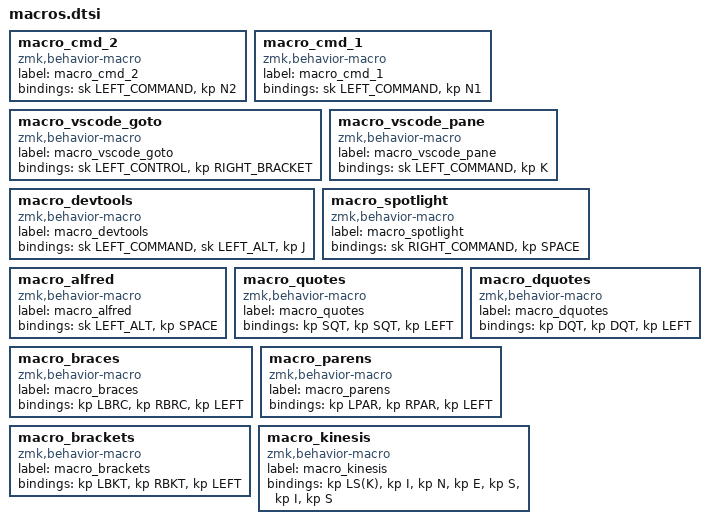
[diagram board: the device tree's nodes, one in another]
macro_cmd_2: macro_cmd_2{
compatible = "zmk,behavior-macro";
label = "macro_cmd_2";
#binding-cells = <0>;
bindings = <&sk LEFT_COMMAND>, <&kp N2>;
};
macro_cmd_1: macro_cmd_1{
compatible = "zmk,behavior-macro";
label = "macro_cmd_1";
#binding-cells = <0>;
bindings = <&sk LEFT_COMMAND>, <&kp N1>;
};
macro_vscode_goto: macro_vscode_goto{
compatible = "zmk,behavior-macro";
label = "macro_vscode_goto";
#binding-cells = <0>;
bindings = <&sk LEFT_CONTROL>, <&kp RIGHT_BRACKET>;
};
macro_vscode_pane: macro_vscode_pane{
compatible = "zmk,behavior-macro";
label = "macro_vscode_pane";
#binding-cells = <0>;
bindings = <&sk LEFT_COMMAND>, <&kp K>;
};
macro_devtools: macro_devtools{
compatible = "zmk,behavior-macro";
label = "macro_devtools";
#binding-cells = <0>;
bindings = <&sk LEFT_COMMAND>, <&sk LEFT_ALT>, <&kp J>;
};
macro_spotlight: macro_spotlight{
compatible = "zmk,behavior-macro";
label = "macro_spotlight";
#binding-cells = <0>;
bindings = <&sk RIGHT_COMMAND>, <&kp SPACE>;
};
macro_alfred: macro_alfred{
compatible = "zmk,behavior-macro";
label = "macro_alfred";
#binding-cells = <0>;
bindings = <&sk LEFT_ALT>, <&kp SPACE>;
};
macro_quotes: macro_quotes{
compatible = "zmk,behavior-macro";
label = "macro_quotes";
#binding-cells = <0>;
bindings = <&kp SQT>, <&kp SQT>, <&kp LEFT>;
};
macro_dquotes: macro_dquotes{
compatible = "zmk,behavior-macro";
label = "macro_dquotes";
#binding-cells = <0>;
bindings = <&kp DQT>, <&kp DQT>, <&kp LEFT>;
};
macro_braces: macro_braces{
compatible = "zmk,behavior-macro";
label = "macro_braces";
#binding-cells = <0>;
bindings = <&kp LBRC>, <&kp RBRC>, <&kp LEFT>;
};
macro_parens: macro_parens{
compatible = "zmk,behavior-macro";
label = "macro_parens";
#binding-cells = <0>;
bindings = <&kp LPAR>, <&kp RPAR>, <&kp LEFT>;
};
macro_brackets: macro_brackets{
compatible = "zmk,behavior-macro";
label = "macro_brackets";
#binding-cells = <0>;
bindings = <&kp LBKT>, <&kp RBKT>, <&kp LEFT>;
};
macro_kinesis: macro_kinesis{
compatible = "zmk,behavior-macro";
label = "macro_kinesis";
#binding-cells = <0>;
bindings = <&kp LS(K)>, <&kp I>, <&kp N>, <&kp E>, <&kp S>, <&kp I>, <&kp S>;
};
